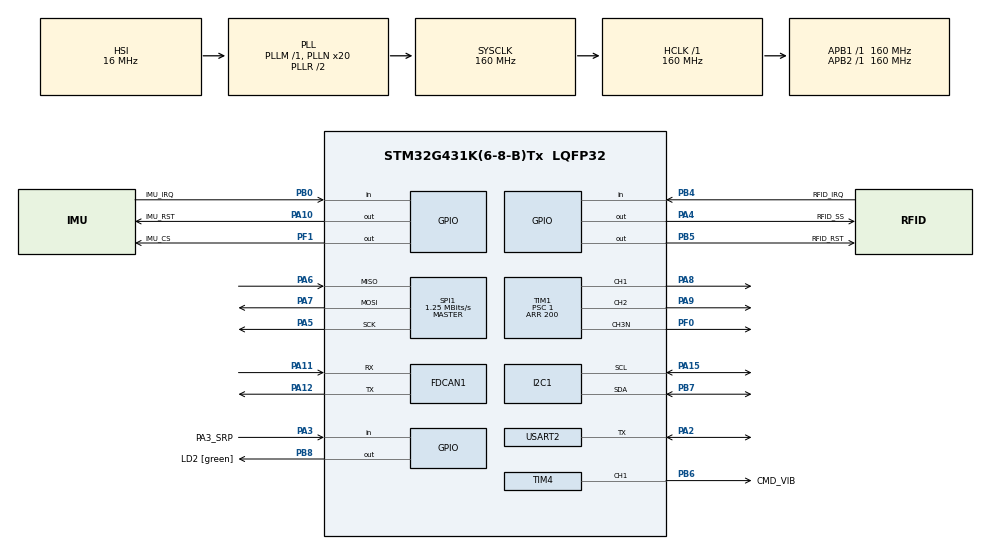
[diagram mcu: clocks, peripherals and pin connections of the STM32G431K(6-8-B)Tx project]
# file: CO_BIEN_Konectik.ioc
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Dma.Request0=TIM1_CH1
Dma.Request1=TIM1_CH3
Dma.Request2=TIM1_CH2
Dma.TIM1_CH1.0.Direction=DMA_MEMORY_TO_PERIPH
Dma.TIM1_CH1.0.EventEnable=DISABLE
Dma.TIM1_CH1.0.Instance=DMA1_Channel1
Dma.TIM1_CH1.0.MemDataAlignment=DMA_MDATAALIGN_HALFWORD
Dma.TIM1_CH1.0.MemInc=DMA_MINC_ENABLE
Dma.TIM1_CH1.0.Mode=DMA_NORMAL
Dma.TIM1_CH1.0.PeriphDataAlignment=DMA_PDATAALIGN_HALFWORD
Dma.TIM1_CH1.0.PeriphInc=DMA_PINC_DISABLE
Dma.TIM1_CH1.0.Polarity=HAL_DMAMUX_REQ_GEN_RISING
Dma.TIM1_CH1.0.Priority=DMA_PRIORITY_LOW
Dma.TIM1_CH1.0.RequestNumber=1
Dma.TIM1_CH1.0.SignalID=NONE
Dma.TIM1_CH1.0.SyncEnable=DISABLE
Dma.TIM1_CH1.0.SyncPolarity=HAL_DMAMUX_SYNC_NO_EVENT
Dma.TIM1_CH1.0.SyncRequestNumber=1
Dma.TIM1_CH1.0.SyncSignalID=NONE
Dma.TIM1_CH2.2.Direction=DMA_MEMORY_TO_PERIPH
Dma.TIM1_CH2.2.EventEnable=DISABLE
Dma.TIM1_CH2.2.Instance=DMA1_Channel3
Dma.TIM1_CH2.2.MemDataAlignment=DMA_MDATAALIGN_HALFWORD
Dma.TIM1_CH2.2.MemInc=DMA_MINC_ENABLE
Dma.TIM1_CH2.2.Mode=DMA_NORMAL
Dma.TIM1_CH2.2.PeriphDataAlignment=DMA_PDATAALIGN_HALFWORD
Dma.TIM1_CH2.2.PeriphInc=DMA_PINC_DISABLE
Dma.TIM1_CH2.2.Polarity=HAL_DMAMUX_REQ_GEN_RISING
Dma.TIM1_CH2.2.Priority=DMA_PRIORITY_LOW
Dma.TIM1_CH2.2.RequestNumber=1
Dma.TIM1_CH2.2.SignalID=NONE
Dma.TIM1_CH2.2.SyncEnable=DISABLE
Dma.TIM1_CH2.2.SyncPolarity=HAL_DMAMUX_SYNC_NO_EVENT
Dma.TIM1_CH2.2.SyncRequestNumber=1
Dma.TIM1_CH2.2.SyncSignalID=NONE
Dma.TIM1_CH3.1.Direction=DMA_MEMORY_TO_PERIPH
Dma.TIM1_CH3.1.EventEnable=DISABLE
Dma.TIM1_CH3.1.Instance=DMA1_Channel2
Dma.TIM1_CH3.1.MemDataAlignment=DMA_MDATAALIGN_HALFWORD
Dma.TIM1_CH3.1.MemInc=DMA_MINC_ENABLE
Dma.TIM1_CH3.1.Mode=DMA_NORMAL
Dma.TIM1_CH3.1.PeriphDataAlignment=DMA_PDATAALIGN_HALFWORD
Dma.TIM1_CH3.1.PeriphInc=DMA_PINC_DISABLE
Dma.TIM1_CH3.1.Polarity=HAL_DMAMUX_REQ_GEN_RISING
Dma.TIM1_CH3.1.Priority=DMA_PRIORITY_LOW
Dma.TIM1_CH3.1.RequestNumber=1
Dma.TIM1_CH3.1.SignalID=NONE
Dma.TIM1_CH3.1.SyncEnable=DISABLE
Dma.TIM1_CH3.1.SyncPolarity=HAL_DMAMUX_SYNC_NO_EVENT
Dma.TIM1_CH3.1.SyncRequestNumber=1
Dma.TIM1_CH3.1.SyncSignalID=NONE
FDCAN1.AutoRetransmission=ENABLE
FDCAN1.CalculateBaudRateNominal=500000
FDCAN1.CalculateTimeBitNominal=2000
FDCAN1.CalculateTimeQuantumNominal=500.0
FDCAN1.ClockDivider=FDCAN_CLOCK_DIV16
FDCAN1.NominalPrescaler=5
FDCAN1.NominalTimeSeg2=2
I2C1.I2C_Fall_Time=0
I2C1.I2C_Rise_Time=0
I2C1.Timing=0x30909DEC
Mcu.Family=STM32G4
Mcu.Name=STM32G431K(6-8-B)Tx
Mcu.Package=LQFP32
NVIC.DMA1_Channel1_IRQn=true\:0\:0\:false\:false\:true\:false\:true\:true
NVIC.DMA1_Channel2_IRQn=true\:0\:0\:false\:false\:true\:false\:true\:true
NVIC.DMA1_Channel3_IRQn=true\:0\:0\:false\:false\:true\:false\:true\:true
NVIC.FDCAN1_IT0_IRQn=true\:0\:0\:false\:false\:true\:true\:true\:true
NVIC.PriorityGroup=NVIC_PRIORITYGROUP_4
PA10.GPIO_Label=IMU_RST
PA10.Signal=GPIO_Output
PA11.Mode=FDCAN_Activate
PA11.Signal=FDCAN1_RX
PA12.Mode=FDCAN_Activate
PA12.Signal=FDCAN1_TX
PA13.GPIO_Label=T_SWDIO
PA13.Mode=Trace_Asynchronous_SW
PA13.Signal=SYS_JTMS-SWDIO
PA14.GPIO_Label=T_SWCLK
PA14.Mode=Trace_Asynchronous_SW
PA14.Signal=SYS_JTCK-SWCLK
PA15.Mode=I2C
PA15.Signal=I2C1_SCL
PA2.Mode=Half_duplex(single_wire_mode)
PA2.Signal=USART2_TX
PA3.GPIO_Label=PA3_SRP
PA3.Signal=GPIO_Input
PA4.GPIO_Label=RFID_SS
PA4.Signal=GPIO_Output
PA5.Mode=Full_Duplex_Master
PA5.Signal=SPI1_SCK
PA6.Mode=Full_Duplex_Master
PA6.Signal=SPI1_MISO
PA7.Mode=Full_Duplex_Master
PA7.Signal=SPI1_MOSI
PA8.Signal=S_TIM1_CH1
PA9.Signal=S_TIM1_CH2
PB0.GPIO_Label=IMU_IRQ
PB0.Signal=GPIO_Input
PB3.GPIO_Label=T_SWO
PB3.Mode=Trace_Asynchronous_SW
PB3.Signal=SYS_JTDO-SWO
PB4.GPIO_Label=RFID_IRQ
PB4.GPIO_PuPd=GPIO_PULLUP
PB4.Signal=GPIO_Input
PB5.GPIO_Label=RFID_RST
PB5.Signal=GPIO_Output
PB6.GPIO_Label=CMD_VIB
PB6.Signal=S_TIM4_CH1
PB7.GPIO_FM7=SYSCFG_FASTMODEPLUS_PB7
PB7.Mode=I2C
PB7.Signal=I2C1_SDA
PB8-BOOT0.GPIO_Label=LD2 [green]
PB8-BOOT0.Signal=GPIO_Output
PF0-OSC_IN.Mode=PWM Generation3 CH3N
PF0-OSC_IN.Signal=TIM1_CH3N
PF1-OSC_OUT.GPIO_Label=IMU_CS
PF1-OSC_OUT.Signal=GPIO_Output
ProjectManager.HeapSize=0x200
ProjectManager.StackSize=0x400
ProjectManager.TargetToolchain=STM32CubeIDE
RCC.ADC12Freq_Value=160000000
RCC.AHBFreq_Value=160000000
RCC.APB1Freq_Value=160000000
RCC.APB1TimFreq_Value=160000000
RCC.APB2Freq_Value=160000000
RCC.APB2TimFreq_Value=160000000
RCC.CortexFreq_Value=160000000
RCC.EXTERNAL_CLOCK_VALUE=12288000
RCC.HCLKFreq_Value=160000000
RCC.HSE_VALUE=8000000
RCC.HSI48_VALUE=48000000
RCC.HSI_VALUE=16000000
RCC.LSE_VALUE=32768
RCC.PLLN=20
RCC.SYSCLKFreq_VALUE=160000000
RCC.SYSCLKSource=RCC_SYSCLKSOURCE_PLLCLK
RCC.USBFreq_Value=160000000
RCC.VCOOutputFreq_Value=320000000
SH.S_TIM1_CH1.0=TIM1_CH1,PWM Generation1 CH1
SH.S_TIM1_CH2.0=TIM1_CH2,PWM Generation2 CH2
SH.S_TIM4_CH1.0=TIM4_CH1,PWM Generation1 CH1
SPI1.BaudRatePrescaler=SPI_BAUDRATEPRESCALER_128
SPI1.CLKPhase=SPI_PHASE_1EDGE
SPI1.CLKPolarity=SPI_POLARITY_LOW
SPI1.CalculateBaudRate=1.25 MBits/s
SPI1.DataSize=SPI_DATASIZE_8BIT
SPI1.Direction=SPI_DIRECTION_2LINES
SPI1.Mode=SPI_MODE_MASTER
SPI1.NSSPMode=SPI_NSS_PULSE_DISABLE
SPI1.VirtualType=VM_MASTER
TIM1.Channel-PWM\ Generation1\ CH1=TIM_CHANNEL_1
TIM1.Channel-PWM\ Generation2\ CH2=TIM_CHANNEL_2
TIM1.Channel-PWM\ Generation3\ CH3N=TIM_CHANNEL_3
TIM1.PeriodNoDither=200
TIM1.Prescaler=1
TIM4.Channel-PWM\ Generation1\ CH1=TIM_CHANNEL_1
TIM4.PeriodNoDither=100-1
TIM4.Prescaler=800-1
USART2.VirtualMode-Half_duplex(single_wire_mode)=VM_ASYNC
VP_SYS_VS_DBSignals.Mode=DisableDeadBatterySignals
board=NUCLEO-G431KB

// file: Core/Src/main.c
/* USER CODE BEGIN Header */
/**
 ******************************************************************************
 * @file           : main.c
 * @brief          : Main program body
 ******************************************************************************
 * @attention
 *
 * Copyright (c) 2025 STMicroelectronics.
 * All rights reserved.
 *
 * This software is licensed under terms that can be found in the LICENSE file
 * in the root directory of this software component.
 * If no LICENSE file comes with this software, it is provided AS-IS.
 *
 ******************************************************************************
 */
/* USER CODE END Header */
#include "main.h"

/* USER CODE BEGIN Includes */

#include "application.h"
/* USER CODE END Includes */

FDCAN_HandleTypeDef hfdcan1;

I2C_HandleTypeDef hi2c1;

SPI_HandleTypeDef hspi1;

TIM_HandleTypeDef htim1;
TIM_HandleTypeDef htim4;
DMA_HandleTypeDef hdma_tim1_ch1;
DMA_HandleTypeDef hdma_tim1_ch3;
DMA_HandleTypeDef hdma_tim1_ch2;

UART_HandleTypeDef huart2;

void SystemClock_Config(void);
static void MX_GPIO_Init(void);
static void MX_DMA_Init(void);
static void MX_USART2_UART_Init(void);
static void MX_I2C1_Init(void);
static void MX_SPI1_Init(void);
static void MX_FDCAN1_Init(void);
static void MX_TIM1_Init(void);
static void MX_TIM4_Init(void);

/* USER CODE BEGIN 0 */
// Redirection du printf sur UART2 (pour une nucleo 64)
int __io_putchar(int ch) {
    HAL_UART_Transmit(&huart2, (uint8_t*) &ch, 1, 100);
    //ITM_SendChar(ch);
    return (ch);
}
/* USER CODE END 0 */

int main(void)
{

  /* MCU Configuration--------------------------------------------------------*/

  /* Reset of all peripherals, Initializes the Flash interface and the Systick. */
  HAL_Init();

  /* Configure the system clock */
  SystemClock_Config();

  /* Initialize all configured peripherals */
  MX_GPIO_Init();
  MX_DMA_Init();
  MX_USART2_UART_Init();
  MX_I2C1_Init();
  MX_SPI1_Init();
  MX_FDCAN1_Init();
  MX_TIM1_Init();
  MX_TIM4_Init();

  /* Infinite loop */
  /* USER CODE BEGIN WHILE */
    my_setup();
    while (1) {
        my_loop();
    /* USER CODE END WHILE */

    }
}

void SystemClock_Config(void)
{
  RCC_OscInitTypeDef RCC_OscInitStruct = {0};
  RCC_ClkInitTypeDef RCC_ClkInitStruct = {0};

  /** Configure the main internal regulator output voltage
  */
  HAL_PWREx_ControlVoltageScaling(PWR_REGULATOR_VOLTAGE_SCALE1_BOOST);

  /** Initializes the RCC Oscillators according to the specified parameters
  * in the RCC_OscInitTypeDef structure.
  */
  RCC_OscInitStruct.OscillatorType = RCC_OSCILLATORTYPE_HSI;
  RCC_OscInitStruct.HSIState = RCC_HSI_ON;
  RCC_OscInitStruct.HSICalibrationValue = RCC_HSICALIBRATION_DEFAULT;
  RCC_OscInitStruct.PLL.PLLState = RCC_PLL_ON;
  RCC_OscInitStruct.PLL.PLLSource = RCC_PLLSOURCE_HSI;
  RCC_OscInitStruct.PLL.PLLM = RCC_PLLM_DIV1;
  RCC_OscInitStruct.PLL.PLLN = 20;
  RCC_OscInitStruct.PLL.PLLP = RCC_PLLP_DIV2;
  RCC_OscInitStruct.PLL.PLLQ = RCC_PLLQ_DIV2;
  RCC_OscInitStruct.PLL.PLLR = RCC_PLLR_DIV2;
  if (HAL_RCC_OscConfig(&RCC_OscInitStruct) != HAL_OK)
  {
    Error_Handler();
  }

  /** Initializes the CPU, AHB and APB buses clocks
  */
  RCC_ClkInitStruct.ClockType = RCC_CLOCKTYPE_HCLK|RCC_CLOCKTYPE_SYSCLK
                              |RCC_CLOCKTYPE_PCLK1|RCC_CLOCKTYPE_PCLK2;
  RCC_ClkInitStruct.SYSCLKSource = RCC_SYSCLKSOURCE_PLLCLK;
  RCC_ClkInitStruct.AHBCLKDivider = RCC_SYSCLK_DIV1;
  RCC_ClkInitStruct.APB1CLKDivider = RCC_HCLK_DIV1;
  RCC_ClkInitStruct.APB2CLKDivider = RCC_HCLK_DIV1;

  if (HAL_RCC_ClockConfig(&RCC_ClkInitStruct, FLASH_LATENCY_4) != HAL_OK)
  {
    Error_Handler();
  }
}

static void MX_FDCAN1_Init(void)
{

  hfdcan1.Instance = FDCAN1;
  hfdcan1.Init.ClockDivider = FDCAN_CLOCK_DIV16;
  hfdcan1.Init.FrameFormat = FDCAN_FRAME_CLASSIC;
  hfdcan1.Init.Mode = FDCAN_MODE_NORMAL;
  hfdcan1.Init.AutoRetransmission = ENABLE;
  hfdcan1.Init.TransmitPause = DISABLE;
  hfdcan1.Init.ProtocolException = DISABLE;
  hfdcan1.Init.NominalPrescaler = 5;
  hfdcan1.Init.NominalSyncJumpWidth = 1;
  hfdcan1.Init.NominalTimeSeg1 = 1;
  hfdcan1.Init.NominalTimeSeg2 = 2;
  hfdcan1.Init.DataPrescaler = 1;
  hfdcan1.Init.DataSyncJumpWidth = 1;
  hfdcan1.Init.DataTimeSeg1 = 1;
  hfdcan1.Init.DataTimeSeg2 = 1;
  hfdcan1.Init.StdFiltersNbr = 0;
  hfdcan1.Init.ExtFiltersNbr = 0;
  hfdcan1.Init.TxFifoQueueMode = FDCAN_TX_FIFO_OPERATION;
  if (HAL_FDCAN_Init(&hfdcan1) != HAL_OK)
  {
    Error_Handler();
  }

}

static void MX_I2C1_Init(void)
{

  hi2c1.Instance = I2C1;
  hi2c1.Init.Timing = 0x30909DEC;
  hi2c1.Init.OwnAddress1 = 0;
  hi2c1.Init.AddressingMode = I2C_ADDRESSINGMODE_7BIT;
  hi2c1.Init.DualAddressMode = I2C_DUALADDRESS_DISABLE;
  hi2c1.Init.OwnAddress2 = 0;
  hi2c1.Init.OwnAddress2Masks = I2C_OA2_NOMASK;
  hi2c1.Init.GeneralCallMode = I2C_GENERALCALL_DISABLE;
  hi2c1.Init.NoStretchMode = I2C_NOSTRETCH_DISABLE;
  if (HAL_I2C_Init(&hi2c1) != HAL_OK)
  {
    Error_Handler();
  }

  /** Configure Analogue filter
  */
  if (HAL_I2CEx_ConfigAnalogFilter(&hi2c1, I2C_ANALOGFILTER_ENABLE) != HAL_OK)
  {
    Error_Handler();
  }

  /** Configure Digital filter
  */
  if (HAL_I2CEx_ConfigDigitalFilter(&hi2c1, 0) != HAL_OK)
  {
    Error_Handler();
  }

}

static void MX_SPI1_Init(void)
{

  /* SPI1 parameter configuration*/
  hspi1.Instance = SPI1;
  hspi1.Init.Mode = SPI_MODE_MASTER;
  hspi1.Init.Direction = SPI_DIRECTION_2LINES;
  hspi1.Init.DataSize = SPI_DATASIZE_8BIT;
  hspi1.Init.CLKPolarity = SPI_POLARITY_LOW;
  hspi1.Init.CLKPhase = SPI_PHASE_1EDGE;
  hspi1.Init.NSS = SPI_NSS_SOFT;
  hspi1.Init.BaudRatePrescaler = SPI_BAUDRATEPRESCALER_128;
  hspi1.Init.FirstBit = SPI_FIRSTBIT_MSB;
  hspi1.Init.TIMode = SPI_TIMODE_DISABLE;
  hspi1.Init.CRCCalculation = SPI_CRCCALCULATION_DISABLE;
  hspi1.Init.CRCPolynomial = 7;
  hspi1.Init.CRCLength = SPI_CRC_LENGTH_DATASIZE;
  hspi1.Init.NSSPMode = SPI_NSS_PULSE_DISABLE;
  if (HAL_SPI_Init(&hspi1) != HAL_OK)
  {
    Error_Handler();
  }

}

static void MX_TIM1_Init(void)
{

  TIM_MasterConfigTypeDef sMasterConfig = {0};
  TIM_OC_InitTypeDef sConfigOC = {0};
  TIM_BreakDeadTimeConfigTypeDef sBreakDeadTimeConfig = {0};

  htim1.Instance = TIM1;
  htim1.Init.Prescaler = 1;
  htim1.Init.CounterMode = TIM_COUNTERMODE_UP;
  htim1.Init.Period = 200;
  htim1.Init.ClockDivision = TIM_CLOCKDIVISION_DIV1;
  htim1.Init.RepetitionCounter = 0;
  htim1.Init.AutoReloadPreload = TIM_AUTORELOAD_PRELOAD_DISABLE;
  if (HAL_TIM_PWM_Init(&htim1) != HAL_OK)
  {
    Error_Handler();
  }
  sMasterConfig.MasterOutputTrigger = TIM_TRGO_RESET;
  sMasterConfig.MasterOutputTrigger2 = TIM_TRGO2_RESET;
  sMasterConfig.MasterSlaveMode = TIM_MASTERSLAVEMODE_DISABLE;
  if (HAL_TIMEx_MasterConfigSynchronization(&htim1, &sMasterConfig) != HAL_OK)
  {
    Error_Handler();
  }
  sConfigOC.OCMode = TIM_OCMODE_PWM1;
  sConfigOC.Pulse = 0;
  sConfigOC.OCPolarity = TIM_OCPOLARITY_HIGH;
  sConfigOC.OCNPolarity = TIM_OCNPOLARITY_HIGH;
  sConfigOC.OCFastMode = TIM_OCFAST_DISABLE;
  sConfigOC.OCIdleState = TIM_OCIDLESTATE_RESET;
  sConfigOC.OCNIdleState = TIM_OCNIDLESTATE_RESET;
  if (HAL_TIM_PWM_ConfigChannel(&htim1, &sConfigOC, TIM_CHANNEL_1) != HAL_OK)
  {
    Error_Handler();
  }
  if (HAL_TIM_PWM_ConfigChannel(&htim1, &sConfigOC, TIM_CHANNEL_2) != HAL_OK)
  {
    Error_Handler();
  }
  if (HAL_TIM_PWM_ConfigChannel(&htim1, &sConfigOC, TIM_CHANNEL_3) != HAL_OK)
  {
    Error_Handler();
  }
  sBreakDeadTimeConfig.OffStateRunMode = TIM_OSSR_DISABLE;
  sBreakDeadTimeConfig.OffStateIDLEMode = TIM_OSSI_DISABLE;
  sBreakDeadTimeConfig.LockLevel = TIM_LOCKLEVEL_OFF;
  sBreakDeadTimeConfig.DeadTime = 0;
  sBreakDeadTimeConfig.BreakState = TIM_BREAK_DISABLE;
  sBreakDeadTimeConfig.BreakPolarity = TIM_BREAKPOLARITY_HIGH;
  sBreakDeadTimeConfig.BreakFilter = 0;
  sBreakDeadTimeConfig.BreakAFMode = TIM_BREAK_AFMODE_INPUT;
  sBreakDeadTimeConfig.Break2State = TIM_BREAK2_DISABLE;
  sBreakDeadTimeConfig.Break2Polarity = TIM_BREAK2POLARITY_HIGH;
  sBreakDeadTimeConfig.Break2Filter = 0;
  sBreakDeadTimeConfig.Break2AFMode = TIM_BREAK_AFMODE_INPUT;
  sBreakDeadTimeConfig.AutomaticOutput = TIM_AUTOMATICOUTPUT_DISABLE;
  if (HAL_TIMEx_ConfigBreakDeadTime(&htim1, &sBreakDeadTimeConfig) != HAL_OK)
  {
    Error_Handler();
  }
  HAL_TIM_MspPostInit(&htim1);

}

static void MX_TIM4_Init(void)
{

  TIM_MasterConfigTypeDef sMasterConfig = {0};
  TIM_OC_InitTypeDef sConfigOC = {0};

  htim4.Instance = TIM4;
  htim4.Init.Prescaler = 800-1;
  htim4.Init.CounterMode = TIM_COUNTERMODE_UP;
  htim4.Init.Period = 99;
  htim4.Init.ClockDivision = TIM_CLOCKDIVISION_DIV1;
  htim4.Init.AutoReloadPreload = TIM_AUTORELOAD_PRELOAD_DISABLE;
  if (HAL_TIM_PWM_Init(&htim4) != HAL_OK)
  {
    Error_Handler();
  }
  sMasterConfig.MasterOutputTrigger = TIM_TRGO_RESET;
  sMasterConfig.MasterSlaveMode = TIM_MASTERSLAVEMODE_DISABLE;
  if (HAL_TIMEx_MasterConfigSynchronization(&htim4, &sMasterConfig) != HAL_OK)
  {
    Error_Handler();
  }
  sConfigOC.OCMode = TIM_OCMODE_PWM1;
  sConfigOC.Pulse = 0;
  sConfigOC.OCPolarity = TIM_OCPOLARITY_HIGH;
  sConfigOC.OCFastMode = TIM_OCFAST_DISABLE;
  if (HAL_TIM_PWM_ConfigChannel(&htim4, &sConfigOC, TIM_CHANNEL_1) != HAL_OK)
  {
    Error_Handler();
  }
  HAL_TIM_MspPostInit(&htim4);

}

static void MX_USART2_UART_Init(void)
{

  huart2.Instance = USART2;
  huart2.Init.BaudRate = 115200;
  huart2.Init.WordLength = UART_WORDLENGTH_8B;
  huart2.Init.StopBits = UART_STOPBITS_1;
  huart2.Init.Parity = UART_PARITY_NONE;
  huart2.Init.Mode = UART_MODE_TX_RX;
  huart2.Init.HwFlowCtl = UART_HWCONTROL_NONE;
  huart2.Init.OverSampling = UART_OVERSAMPLING_16;
  huart2.Init.OneBitSampling = UART_ONE_BIT_SAMPLE_DISABLE;
  huart2.Init.ClockPrescaler = UART_PRESCALER_DIV1;
  huart2.AdvancedInit.AdvFeatureInit = UART_ADVFEATURE_NO_INIT;
  if (HAL_HalfDuplex_Init(&huart2) != HAL_OK)
  {
    Error_Handler();
  }
  if (HAL_UARTEx_SetTxFifoThreshold(&huart2, UART_TXFIFO_THRESHOLD_1_8) != HAL_OK)
  {
    Error_Handler();
  }
  if (HAL_UARTEx_SetRxFifoThreshold(&huart2, UART_RXFIFO_THRESHOLD_1_8) != HAL_OK)
  {
    Error_Handler();
  }
  if (HAL_UARTEx_DisableFifoMode(&huart2) != HAL_OK)
  {
    Error_Handler();
  }

}

static void MX_DMA_Init(void)
{

  /* DMA controller clock enable */
  __HAL_RCC_DMAMUX1_CLK_ENABLE();
  __HAL_RCC_DMA1_CLK_ENABLE();

  /* DMA interrupt init */
  /* DMA1_Channel1_IRQn interrupt configuration */
  HAL_NVIC_SetPriority(DMA1_Channel1_IRQn, 0, 0);
  HAL_NVIC_EnableIRQ(DMA1_Channel1_IRQn);
  /* DMA1_Channel2_IRQn interrupt configuration */
  HAL_NVIC_SetPriority(DMA1_Channel2_IRQn, 0, 0);
  HAL_NVIC_EnableIRQ(DMA1_Channel2_IRQn);
  /* DMA1_Channel3_IRQn interrupt configuration */
  HAL_NVIC_SetPriority(DMA1_Channel3_IRQn, 0, 0);
  HAL_NVIC_EnableIRQ(DMA1_Channel3_IRQn);

}

static void MX_GPIO_Init(void)
{
  GPIO_InitTypeDef GPIO_InitStruct = {0};

  /* GPIO Ports Clock Enable */
  __HAL_RCC_GPIOF_CLK_ENABLE();
  __HAL_RCC_GPIOA_CLK_ENABLE();
  __HAL_RCC_GPIOB_CLK_ENABLE();

  /*Configure GPIO pin Output Level */
  HAL_GPIO_WritePin(IMU_CS_GPIO_Port, IMU_CS_Pin, GPIO_PIN_RESET);

  /*Configure GPIO pin Output Level */
  HAL_GPIO_WritePin(GPIOA, RFID_SS_Pin|IMU_RST_Pin, GPIO_PIN_RESET);

  /*Configure GPIO pin Output Level */
  HAL_GPIO_WritePin(GPIOB, RFID_RST_Pin|LD2_Pin, GPIO_PIN_RESET);

  /*Configure GPIO pin : IMU_CS_Pin */
  GPIO_InitStruct.Pin = IMU_CS_Pin;
  GPIO_InitStruct.Mode = GPIO_MODE_OUTPUT_PP;
  GPIO_InitStruct.Pull = GPIO_NOPULL;
  GPIO_InitStruct.Speed = GPIO_SPEED_FREQ_LOW;
  HAL_GPIO_Init(IMU_CS_GPIO_Port, &GPIO_InitStruct);

  /*Configure GPIO pin : PA3_SRP_Pin */
  GPIO_InitStruct.Pin = PA3_SRP_Pin;
  GPIO_InitStruct.Mode = GPIO_MODE_INPUT;
  GPIO_InitStruct.Pull = GPIO_NOPULL;
  HAL_GPIO_Init(PA3_SRP_GPIO_Port, &GPIO_InitStruct);

  /*Configure GPIO pins : RFID_SS_Pin IMU_RST_Pin */
  GPIO_InitStruct.Pin = RFID_SS_Pin|IMU_RST_Pin;
  GPIO_InitStruct.Mode = GPIO_MODE_OUTPUT_PP;
  GPIO_InitStruct.Pull = GPIO_NOPULL;
  GPIO_InitStruct.Speed = GPIO_SPEED_FREQ_LOW;
  HAL_GPIO_Init(GPIOA, &GPIO_InitStruct);

  /*Configure GPIO pin : IMU_IRQ_Pin */
  GPIO_InitStruct.Pin = IMU_IRQ_Pin;
  GPIO_InitStruct.Mode = GPIO_MODE_INPUT;
  GPIO_InitStruct.Pull = GPIO_NOPULL;
  HAL_GPIO_Init(IMU_IRQ_GPIO_Port, &GPIO_InitStruct);

  /*Configure GPIO pin : RFID_IRQ_Pin */
  GPIO_InitStruct.Pin = RFID_IRQ_Pin;
  GPIO_InitStruct.Mode = GPIO_MODE_INPUT;
  GPIO_InitStruct.Pull = GPIO_PULLUP;
  HAL_GPIO_Init(RFID_IRQ_GPIO_Port, &GPIO_InitStruct);

  /*Configure GPIO pins : RFID_RST_Pin LD2_Pin */
  GPIO_InitStruct.Pin = RFID_RST_Pin|LD2_Pin;
  GPIO_InitStruct.Mode = GPIO_MODE_OUTPUT_PP;
  GPIO_InitStruct.Pull = GPIO_NOPULL;
  GPIO_InitStruct.Speed = GPIO_SPEED_FREQ_LOW;
  HAL_GPIO_Init(GPIOB, &GPIO_InitStruct);

}

void Error_Handler(void)
{
  /* USER CODE BEGIN Error_Handler_Debug */
    /* User can add his own implementation to report the HAL error return state */
    __disable_irq();
    while (1) {
        for (int n = 0; n < 1000; n++) {
            HAL_GPIO_TogglePin(LD2_GPIO_Port, LD2_Pin);
            for (uint64_t i = 0; i < 150000; i++) {
                __asm__("nop");
            }
        }
        // HAL_Delay (50); //plus d'it, donc plus de tick
        NVIC_SystemReset();
    }
  /* USER CODE END Error_Handler_Debug */
}
